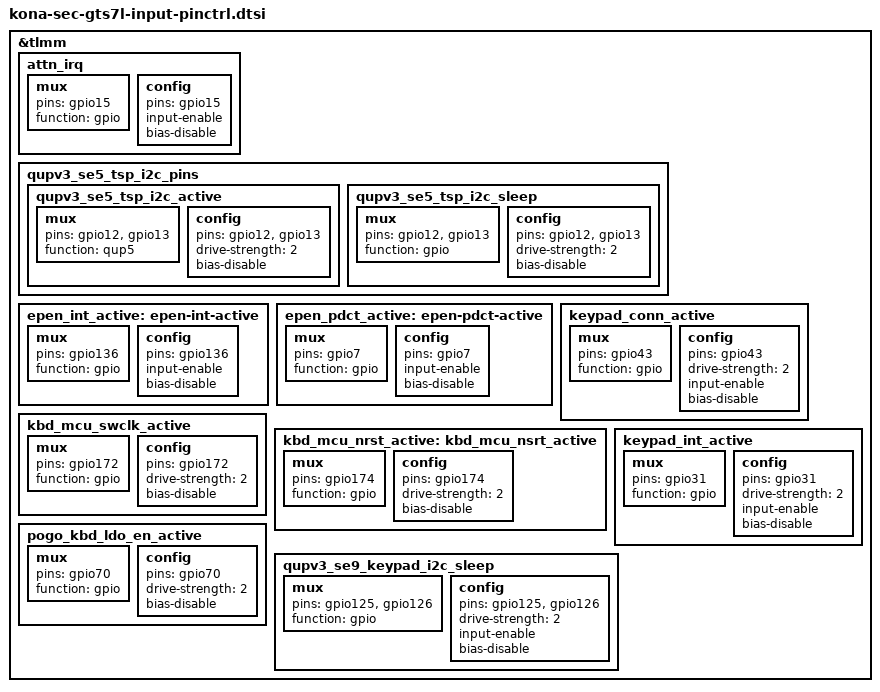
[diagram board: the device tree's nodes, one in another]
/* Copyright (c) 2019, The Linux Foundation. All rights reserved.
 *
 * This program is free software; you can redistribute it and/or modify
 * it under the terms of the GNU General Public License version 2 and
 * only version 2 as published by the Free Software Foundation.
 *
 * This program is distributed in the hope that it will be useful,
 * but WITHOUT ANY WARRANTY; without even the implied warranty of
 * MERCHANTABILITY or FITNESS FOR A PARTICULAR PURPOSE.  See the
 * GNU General Public License for more details.
 */

&tlmm {
	attn_irq: attn_irq {
		mux {
			pins = "gpio15";
			function = "gpio";
		};
		config {
			pins = "gpio15";
			input-enable;
			bias-disable;
		};
	};

	/* SE 5 pin mappings */
	qupv3_se5_tsp_i2c_pins: qupv3_se5_tsp_i2c_pins {
		qupv3_se5_tsp_i2c_active: qupv3_se5_tsp_i2c_active {
			mux {
				pins = "gpio12", "gpio13";
				function = "qup5";
			};

			config {
				pins = "gpio12", "gpio13";
				drive-strength = <2>;
				bias-disable;
			};
		};

		qupv3_se5_tsp_i2c_sleep: qupv3_se5_tsp_i2c_sleep {
			mux {
				pins = "gpio12", "gpio13";
				function = "gpio";
			};

			config {
				pins = "gpio12", "gpio13";
				drive-strength = <2>;
				bias-disable;
			};
		};
	};

	epen_int_active: epen-int-active {
		mux {
			pins = "gpio136";
			function = "gpio";
		};
		config {
			pins = "gpio136";
			input-enable;
			bias-disable; /* No PULL */
		};
	};

	epen_pdct_active: epen-pdct-active {
		mux {
			pins = "gpio7";
			function = "gpio";
		};
		config {
			pins = "gpio7";
			input-enable;
			bias-disable;
		};
	};

		/* pogo keyboard int pinctrl */
	keypad_conn_active: keypad_conn_active {
		mux {
			pins = "gpio43";
			function = "gpio";
		};

		config {
			pins = "gpio43";
			drive-strength = <2>;
			input-enable;
			bias-disable;
		};
	};

	kbd_mcu_swclk_active: kbd_mcu_swclk_active {
		mux {
			pins = "gpio172";
			function = "gpio";
		};

		config {
			pins = "gpio172";
			drive-strength = <2>;
			bias-disable;
		};
	};

	kbd_mcu_nrst_active: kbd_mcu_nsrt_active {
		mux {
			pins = "gpio174";
			function = "gpio";
		};

		config {
			pins = "gpio174";
			drive-strength = <2>;
			bias-disable;
		};
	};

	keypad_int_active: keypad_int_active {
		mux {
			pins = "gpio31";
			function = "gpio";
		};

		config {
			pins = "gpio31";
			drive-strength = <2>;
			input-enable;
			bias-disable;
		};
	};

	pogo_kbd_ldo_en_active: pogo_kbd_ldo_en_active {
		mux {
			pins = "gpio70";
			function = "gpio";
		};

		config {
			pins = "gpio70";
			drive-strength = <2>;
			bias-disable;
		};
	};

	qupv3_se9_keypad_i2c_sleep: qupv3_se9_keypad_i2c_sleep {
		mux {
			pins = "gpio125", "gpio126";
			function = "gpio";
		};

		config {
			pins = "gpio125", "gpio126";
			drive-strength = <2>;
			input-enable;
			bias-disable;
		};
	};

};
